# RE01_1500KB register map
Vendor: Renesas Electronics Corporation; Series: RE01_1500KB; File version: 1.20
CPU: CM0PLUS r0p1, little endian, MPU, no FPU, VTOR, 2 interrupt priority bits
Registers are 8-bit, read-write, reset 0x0 unless marked. A register's access mark holds for its fields unless they carry their own. Offsets are from the block's base; [hi:lo] are bit positions.

## DMAC0 — Direct Memory Access Controller Interface 0
Base 0x40005000
Same registers: DMAC1 0x40005040, DMAC2 0x40005080, DMAC3 0x400050C0
0x00 DMSAR 32-bit — DMA Source Address Register
  [31:0] DMSAR — Set DMSAR while DMAC activation is disabled (the DMST bit in DMAST = 0) or DMA transfer is disabled (the DTEbit in DMCNT = 0).Note: Address alignment in this register must match the transfer data size value selected in the SZ bit in DMTMD.
0x04 DMDAR 32-bit — DMA Destination Address Register
  [31:0] DMDAR — Set DMDAR while DMAC activation is disabled (the DMST bit in DMAST = 0) or DMA transfer is disabled (the DTEbit in DMCNT = 0).Note: Address alignment in this register must match the transfer data size value selected in the SZ bit in DMTMD.
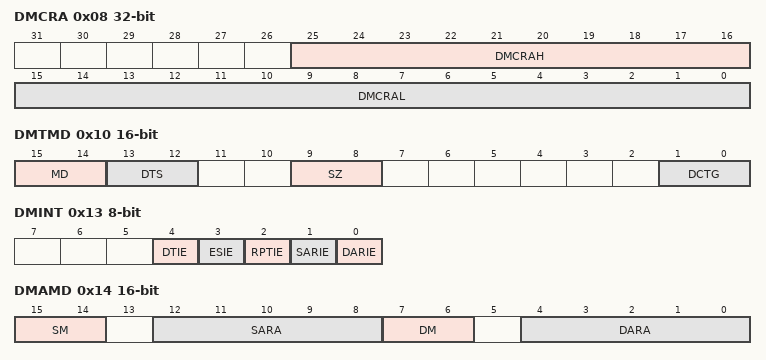
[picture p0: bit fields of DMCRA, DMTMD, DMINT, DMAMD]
0x08 DMCRA 32-bit — DMA Transfer Count Register
  [25:16] DMCRAH — Upper bits of transfer count
  [15:0] DMCRAL — Lower bits of transfer count
0x0C DMCRB 16-bit — DMA Block Transfer Count Register
  [15:0] DMCRB — Specifies the number of block transfer operations or repeat transfer operations.0001h to FFFFh: (1 to 65,535)0000h: (65,536)
0x10 DMTMD 16-bit — DMA Transfer Mode Register
  [15:14] MD — Transfer Mode Select
    0=Normal transfer; 1=Repeat transfer; 2=Block transfer; 3=Setting prohibited
  [13:12] DTS — Repeat Area Select
    0=The destination is specified as the repeat area or block area; 1=The source is specified as the repeat area or block area; 2=The repeat area or block area is not specified; 3=Setting prohibited
  [9:8] SZ — Transfer Data Size Select
    0=8 bits; 1=16 bits; 2=32 bits; 3=Setting prohibited
  [1:0] DCTG — Transfer Request Source Select
    0=Software; 1=Interrupts from peripheral modules or external interrupt input pins; 2=Setting prohibited; 3=Setting prohibited
0x13 DMINT — DMA Interrupt Setting Register
  [all] fields
    0=Disabled; 1=Enabled
  [4] DTIE — Transfer End Interrupt Enable
  [3] ESIE — Transfer Escape End Interrupt Enable
  [2] RPTIE — Repeat Size End Interrupt Enable
  [1] SARIE — Source Address Extended Repeat Area Overflow Interrupt Enable
  [0] DARIE — Destination Address Extended Repeat Area Overflow Interrupt Enable
0x14 DMAMD 16-bit — DMA Address Mode Register
  [15:14] SM — Source Address Update Mode
    0=Source address is fixed; 1=Offset addition; 2=Destination address is incremented; 3=Destination address is decremented
  [12:8] SARA — Source Address Extended Repeat Area
  [7:6] DM — Destination Address Update Mode
    0=Destination address is fixed; 1=Offset addition; 2=Destination address is incremented; 3=Destination address is decremented
  [4:0] DARA — Destination Address Extended Repeat Area
0x18 DMOFR 32-bit — DMA Offset Register
  [31:0] DMOFR — Specifies the offset when offset addition is selected as the address update mode for transfer source or destination.
    0=0000 0000h (to 00FF FFFFh : 0 bytes to (16 MB - 1 byte)); 0xFF000000=FF00 0000h (to FFFF FFFFh : -16 MB to -1 byte)
0x1C DMCNT — DMA Transfer Enable Register
  [0] DTE — DMA Transfer Enable
    0=Disabled; 1=Enabled
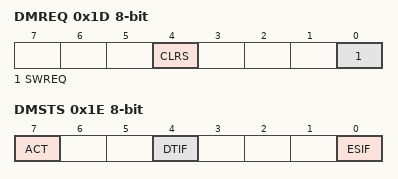
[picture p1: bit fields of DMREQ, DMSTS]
0x1D DMREQ — DMA Software Start Register
  [4] CLRS — DMA Software Start Bit Auto Clear Select
    0=SWREQ bit is cleared after DMA transfer is started by software; 1=SWREQ bit is not cleared after DMA transfer is started by software
  [0] SWREQ — DMA Software Start
    0=DMA transfer is not requested; 1=DMA transfer is requested
0x1E DMSTS — DMA Status Register
  [7] ACT ro — DMA Active Flag
    0=DMAC operation suspended; 1=DMAC operating
  [4] DTIF — Transfer End Interrupt Flag
    0=No interrupt; 1=Interrupt occurred
  [0] ESIF — Transfer Escape End Interrupt Flag
    0=No interrupt; 1=Interrupt occurred
